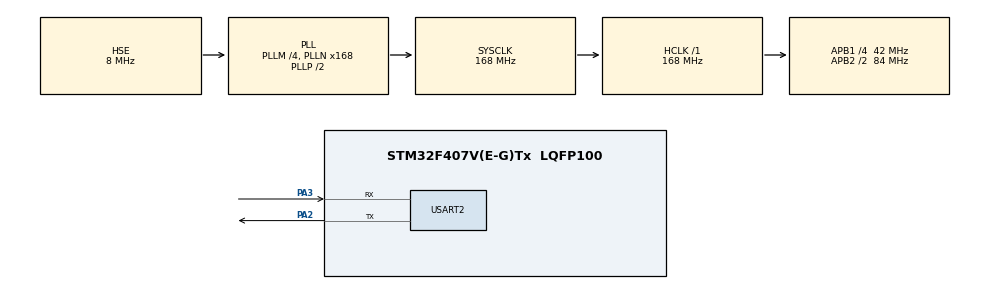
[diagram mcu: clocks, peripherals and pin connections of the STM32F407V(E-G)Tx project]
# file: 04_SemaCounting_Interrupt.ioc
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FREERTOS.Tasks01=defaultTask,0,128,StartDefaultTask,Default,NULL,Dynamic,NULL,NULL
Mcu.Family=STM32F4
Mcu.Name=STM32F407V(E-G)Tx
Mcu.Package=LQFP100
NVIC.PriorityGroup=NVIC_PRIORITYGROUP_4
NVIC.TIM1_UP_TIM10_IRQn=true\:15\:0\:false\:false\:true\:false\:false\:true\:true
NVIC.TimeBase=TIM1_UP_TIM10_IRQn
NVIC.TimeBaseIP=TIM1
NVIC.USART2_IRQn=true\:5\:0\:false\:false\:true\:true\:true\:true\:true
PA2.Mode=Asynchronous
PA2.Signal=USART2_TX
PA3.Mode=Asynchronous
PA3.Signal=USART2_RX
PH0-OSC_IN.Mode=HSE-External-Oscillator
PH0-OSC_IN.Signal=RCC_OSC_IN
PH1-OSC_OUT.Mode=HSE-External-Oscillator
PH1-OSC_OUT.Signal=RCC_OSC_OUT
ProjectManager.HeapSize=0x200
ProjectManager.StackSize=0x400
ProjectManager.TargetToolchain=STM32CubeIDE
RCC.48MHZClocksFreq_Value=84000000
RCC.AHBFreq_Value=168000000
RCC.APB1CLKDivider=RCC_HCLK_DIV4
RCC.APB1Freq_Value=42000000
RCC.APB1TimFreq_Value=84000000
RCC.APB2CLKDivider=RCC_HCLK_DIV2
RCC.APB2Freq_Value=84000000
RCC.APB2TimFreq_Value=168000000
RCC.CortexFreq_Value=168000000
RCC.HCLKFreq_Value=168000000
RCC.HSE_VALUE=8000000
RCC.HSI_VALUE=16000000
RCC.LSE_VALUE=32768
RCC.PLLM=4
RCC.PLLN=168
RCC.PLLSourceVirtual=RCC_PLLSOURCE_HSE
RCC.SYSCLKFreq_VALUE=168000000
RCC.SYSCLKSource=RCC_SYSCLKSOURCE_PLLCLK
RCC.VCOOutputFreq_Value=336000000
USART2.VirtualMode=VM_ASYNC
VP_FREERTOS_VS_CMSIS_V1.Mode=CMSIS_V1
VP_SYS_VS_tim1.Mode=TIM1
board=custom

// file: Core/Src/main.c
/* USER CODE BEGIN Header */
/**
 ******************************************************************************
 * @file           : main.c
 * @brief          : Main program body
 ******************************************************************************
 * @attention
 *
 * Copyright (c) 2024 STMicroelectronics.
 * All rights reserved.
 *
 * This software is licensed under terms that can be found in the LICENSE file
 * in the root directory of this software component.
 * If no LICENSE file comes with this software, it is provided AS-IS.
 *
 ******************************************************************************
 */
/* USER CODE END Header */
#include "main.h"
#include "cmsis_os.h"

/* USER CODE BEGIN Includes */
#include "FreeRTOS.h"
#include "task.h"
#include "timers.h"
#include "queue.h"
#include "semphr.h"
#include "event_groups.h"

#include "string.h"
#include "stdio.h"
/* USER CODE END Includes */

UART_HandleTypeDef huart2;

void SystemClock_Config(void);
static void MX_GPIO_Init(void);
static void MX_USART2_UART_Init(void);

/* USER CODE BEGIN 0 */
xTaskHandle Sender1_Handler;
xTaskHandle Sender2_Handler;
xTaskHandle Receiver_Handler;

xQueueHandle SimpleQueue;

void Sender1_Task(void *argument);
void Sender2_Task(void *argument);
void Receiver_Task(void *argument);

uint8_t rx_data;
/* USER CODE END 0 */

int main(void)
{

  /* MCU Configuration--------------------------------------------------------*/

  /* Reset of all peripherals, Initializes the Flash interface and the Systick. */
  HAL_Init();

  /* Configure the system clock */
  SystemClock_Config();

  /* Initialize all configured peripherals */
  MX_GPIO_Init();
  MX_USART2_UART_Init();
  /* USER CODE BEGIN 2 */

  SimpleQueue = xQueueCreate(10, sizeof(int));

  if (SimpleQueue == 0)
  {
    char *str = "Unable Queue";
    HAL_UART_Transmit(&huart2, (uint8_t *)str, strlen(str), HAL_MAX_DELAY);
  }
  else
  {
    char *str = "Create Queue success\n";
    HAL_UART_Transmit(&huart2, (uint8_t *)str, strlen(str), HAL_MAX_DELAY);
  }

  xTaskCreate(Sender1_Task, "High-Task", 128, NULL, 3, &Sender1_Handler);
  xTaskCreate(Sender2_Task, "Medium-Task", 128, (void *)1, 2, &Sender2_Handler);
  xTaskCreate(Receiver_Task, "Receive-Task", 128, NULL, 1, &Receiver_Handler);

  HAL_UART_Receive_IT(&huart2, &rx_data, 1);

  vTaskStartScheduler();
  /* USER CODE END 2 */

  /* Infinite loop */
  while (1)
  {

  }
}

void SystemClock_Config(void)
{
  RCC_OscInitTypeDef RCC_OscInitStruct = {0};
  RCC_ClkInitTypeDef RCC_ClkInitStruct = {0};

  /** Configure the main internal regulator output voltage
   */
  __HAL_RCC_PWR_CLK_ENABLE();
  __HAL_PWR_VOLTAGESCALING_CONFIG(PWR_REGULATOR_VOLTAGE_SCALE1);

  /** Initializes the RCC Oscillators according to the specified parameters
   * in the RCC_OscInitTypeDef structure.
   */
  RCC_OscInitStruct.OscillatorType = RCC_OSCILLATORTYPE_HSE;
  RCC_OscInitStruct.HSEState = RCC_HSE_ON;
  RCC_OscInitStruct.PLL.PLLState = RCC_PLL_ON;
  RCC_OscInitStruct.PLL.PLLSource = RCC_PLLSOURCE_HSE;
  RCC_OscInitStruct.PLL.PLLM = 4;
  RCC_OscInitStruct.PLL.PLLN = 168;
  RCC_OscInitStruct.PLL.PLLP = RCC_PLLP_DIV2;
  RCC_OscInitStruct.PLL.PLLQ = 4;
  if (HAL_RCC_OscConfig(&RCC_OscInitStruct) != HAL_OK)
  {
    Error_Handler();
  }

  /** Initializes the CPU, AHB and APB buses clocks
   */
  RCC_ClkInitStruct.ClockType = RCC_CLOCKTYPE_HCLK | RCC_CLOCKTYPE_SYSCLK | RCC_CLOCKTYPE_PCLK1 | RCC_CLOCKTYPE_PCLK2;
  RCC_ClkInitStruct.SYSCLKSource = RCC_SYSCLKSOURCE_PLLCLK;
  RCC_ClkInitStruct.AHBCLKDivider = RCC_SYSCLK_DIV1;
  RCC_ClkInitStruct.APB1CLKDivider = RCC_HCLK_DIV4;
  RCC_ClkInitStruct.APB2CLKDivider = RCC_HCLK_DIV2;

  if (HAL_RCC_ClockConfig(&RCC_ClkInitStruct, FLASH_LATENCY_5) != HAL_OK)
  {
    Error_Handler();
  }
}

static void MX_USART2_UART_Init(void)
{

  huart2.Instance = USART2;
  huart2.Init.BaudRate = 115200;
  huart2.Init.WordLength = UART_WORDLENGTH_8B;
  huart2.Init.StopBits = UART_STOPBITS_1;
  huart2.Init.Parity = UART_PARITY_NONE;
  huart2.Init.Mode = UART_MODE_TX_RX;
  huart2.Init.HwFlowCtl = UART_HWCONTROL_NONE;
  huart2.Init.OverSampling = UART_OVERSAMPLING_16;
  if (HAL_UART_Init(&huart2) != HAL_OK)
  {
    Error_Handler();
  }
}

static void MX_GPIO_Init(void)
{

  /* GPIO Ports Clock Enable */
  __HAL_RCC_GPIOH_CLK_ENABLE();
  __HAL_RCC_GPIOA_CLK_ENABLE();

}

/* USER CODE BEGIN 4 */
void Sender1_Task(void *argument)
{
  int i = 2;
  uint32_t TickDelay = pdMS_TO_TICKS(2000);
  while (1)
  {
    char *str = "Enter Task-1 & send data to queue\n";
    HAL_UART_Transmit(&huart2, (uint8_t *)str, strlen(str), HAL_MAX_DELAY);

    if (xQueueSend(SimpleQueue, &i, portMAX_DELAY) == pdPASS)
    {
      char *str1 = "Send Success & leave the Task-1\n\n\n";
      HAL_UART_Transmit(&huart2, (uint8_t *)str1, strlen(str1), HAL_MAX_DELAY);
    }
    vTaskDelay(TickDelay);
  }
}

void Sender2_Task(void *argument)
{
  int tosend;
  uint32_t TickDelay = pdMS_TO_TICKS(1000);
  while (1)
  {
    tosend = (int)argument;
    char *str = "Enter Task-2 & send data to queue\n";
    HAL_UART_Transmit(&huart2, (uint8_t *)str, strlen(str), HAL_MAX_DELAY);

    xQueueSend(SimpleQueue, &tosend, portMAX_DELAY);

    char *str1 = "Send Success & leave the Task-2\n\n\n";
    HAL_UART_Transmit(&huart2, (uint8_t *)str1, strlen(str1), HAL_MAX_DELAY);
    vTaskDelay(TickDelay);
  }
}

void Receiver_Task(void *argument)
{
  int receive = 0;
  uint32_t TickDelay = pdMS_TO_TICKS(1000);

  while (1)
  {
    char str[100];
    strcpy(str, "Enter Receive");
    if (xQueueReceive(SimpleQueue, &receive, portMAX_DELAY) != pdTRUE)
    {
      char *str = "Error in Receive\n\n";
      HAL_UART_Transmit(&huart2, (uint8_t *)str, strlen(str), 1000);
    }
    else
    {
      sprintf(str, " Receive success %d and leave Receive Task\n\n\n", receive);
      HAL_UART_Transmit(&huart2, (uint8_t *)str, strlen(str), HAL_MAX_DELAY);
    }

    vTaskDelay(TickDelay);
  }
}

void HAL_UART_RxCpltCallback(UART_HandleTypeDef *huart)
{
  HAL_UART_Receive_IT(huart, &rx_data, 1);
  int tosend = 3;
  if (rx_data == 'r')
  {
    /* The xHigherPriorityTaskWoken parameter must be initialized to pdFALSE as
    it will get set to pdTRUE inside the interrupt safe API function if a
    context switch is required. */
    BaseType_t xHigherPriorityTaskWoken = pdFALSE;

    if (xQueueSendToFrontFromISR(SimpleQueue, &tosend, &xHigherPriorityTaskWoken) == pdPASS)
    {
      HAL_UART_Transmit(huart, (uint8_t *)"\n\nSent from ISR\n\n", 17, 500);
    }

    /* Pass the xHigherPriorityTaskWoken value into portEND_SWITCHING_ISR(). If
     xHigherPriorityTaskWoken was set to pdTRUE inside xSemaphoreGiveFromISR()
     then calling portEND_SWITCHING_ISR() will request a context switch. If
     xHigherPriorityTaskWoken is still pdFALSE then calling
     portEND_SWITCHING_ISR() will have no effect */

    portEND_SWITCHING_ISR(xHigherPriorityTaskWoken);
  }
}
/* USER CODE END 4 */

void HAL_TIM_PeriodElapsedCallback(TIM_HandleTypeDef *htim)
{
  if (htim->Instance == TIM1)
  {
    HAL_IncTick();
  }
}

void Error_Handler(void)
{
  __disable_irq();
  while (1)
  {
  }
}
